VERSION ""

NS_ :

BS_:

BU_: Tester MCU

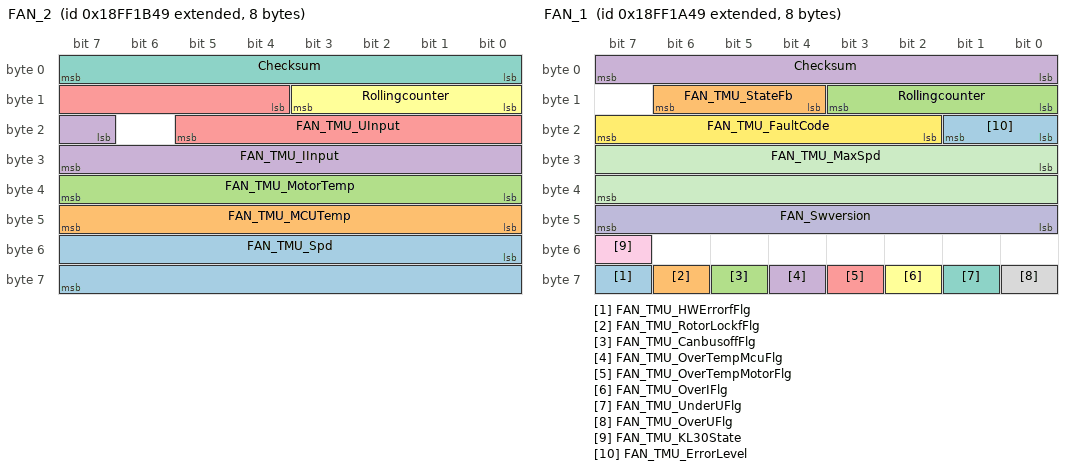
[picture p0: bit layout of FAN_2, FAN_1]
BO_ 2566855497 FAN_2: 8 MCU
 SG_ FAN_TMU_Spd : 48|16@1+ (1,0) [0|6500] ""  Tester
 SG_ FAN_TMU_MCUTemp : 40|8@1+ (1,-40) [-40|210] ""  Tester
 SG_ FAN_TMU_MotorTemp : 32|8@1+ (1,-40) [-40|210] ""  Tester
 SG_ FAN_TMU_IInput : 23|9@1+ (0.1,0) [0|51] ""  Tester
 SG_ FAN_TMU_UInput : 12|10@1+ (1,0) [0|1023] ""  Tester
 SG_ Rollingcounter : 8|4@1+ (1,0) [0|15] ""  Tester
 SG_ Checksum : 0|8@1+ (1,0) [0|255] ""  Tester

BO_ 2566855241 FAN_1: 8 MCU
 SG_ FAN_TMU_HWErrorfFlg : 63|1@1+ (1,0) [0|1] ""  Tester
 SG_ FAN_TMU_RotorLockfFlg : 62|1@1+ (1,0) [0|1] ""  Tester
 SG_ FAN_TMU_CanbusoffFlg : 61|1@1+ (1,0) [0|1] ""  Tester
 SG_ FAN_TMU_OverTempMcuFlg : 60|1@1+ (1,0) [0|1] ""  Tester
 SG_ FAN_TMU_OverTempMotorFlg : 59|1@1+ (1,0) [0|1] ""  Tester
 SG_ FAN_TMU_OverIFlg : 58|1@1+ (1,0) [0|1] ""  Tester
 SG_ FAN_TMU_UnderUFlg : 57|1@1+ (1,0) [0|1] ""  Tester
 SG_ FAN_TMU_OverUFlg : 56|1@1+ (1,0) [0|1] ""  Tester
 SG_ FAN_TMU_KL30State : 55|1@1+ (1,0) [0|1] ""  Tester
 SG_ FAN_Swversion : 40|8@1+ (1,0) [0|255] ""  Tester
 SG_ FAN_TMU_MaxSpd : 24|16@1+ (1,0) [0|6500] ""  Tester
 SG_ FAN_TMU_FaultCode : 18|6@1+ (1,0) [0|63] ""  Tester
 SG_ FAN_TMU_ErrorLevel : 16|2@1+ (1,0) [0|3] ""  Tester
 SG_ FAN_TMU_StateFb : 12|3@1+ (1,0) [0|7] ""  Tester
 SG_ Rollingcounter : 8|4@1+ (1,0) [0|15] ""  Tester
 SG_ Checksum : 0|8@1+ (1,0) [0|255] ""  Tester

BO_ 2566864921 A6_TMU_11: 8 Tester
 SG_ TMU_FAN_SpdReq : 45|16@1+ (1,0) [0|6500] ""  MCU
 SG_ TMU_FAN_ModeReq : 42|3@1+ (1,0) [0|7] ""  MCU

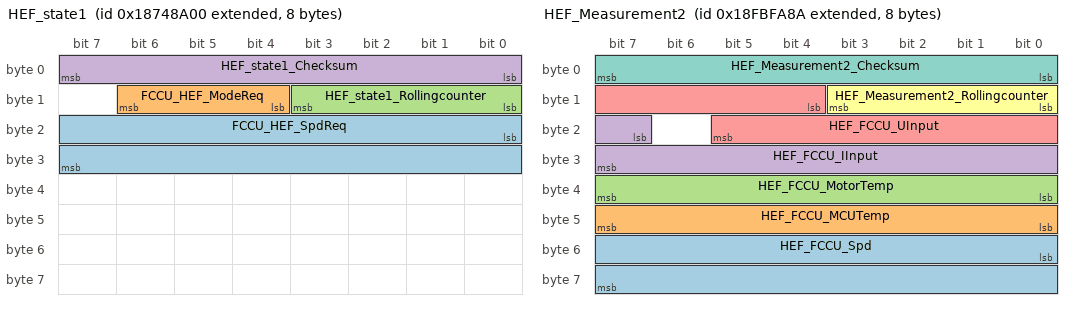
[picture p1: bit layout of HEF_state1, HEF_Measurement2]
BO_ 2557774336 HEF_state1: 8 Tester
 SG_ FCCU_HEF_SpdReq : 16|16@1+ (1,0) [0|6500] "rpm"  MCU
 SG_ FCCU_HEF_ModeReq : 12|3@1+ (1,0) [0|7] ""  MCU
 SG_ HEF_state1_Rollingcounter : 8|4@1+ (1,0) [0|15] ""  MCU
 SG_ HEF_state1_Checksum : 0|8@1+ (1,0) [0|255] ""  MCU

BO_ 2566650506 HEF_Measurement2: 8 MCU
 SG_ HEF_FCCU_Spd : 48|16@1+ (1,0) [0|6500] "rpm"  Tester
 SG_ HEF_FCCU_MCUTemp : 40|8@1+ (1,-40) [-40|210] ""  Tester
 SG_ HEF_FCCU_MotorTemp : 32|8@1+ (1,-40) [-40|210] ""  Tester
 SG_ HEF_FCCU_IInput : 23|9@1+ (0.1,0) [0|51] "A"  Tester
 SG_ HEF_FCCU_UInput : 12|10@1+ (1,0) [0|1023] "V"  Tester
 SG_ HEF_Measurement2_Rollingcounter : 8|4@1+ (1,0) [0|15] ""  Tester
 SG_ HEF_Measurement2_Checksum : 0|8@1+ (1,0) [0|255] ""  Tester

BO_ 2566649994 HEF_Measurement1: 8 MCU
 SG_ HEF_FCCU_HWErrorfFlg : 63|1@1+ (1,0) [0|1] ""  Tester
 SG_ HEF_FCCU_RotorLockfFlg : 62|1@1+ (1,0) [0|1] ""  Tester
 SG_ HEF_FCCU_CanbusoffFlg : 61|1@1+ (1,0) [0|1] ""  Tester
 SG_ HEF_FCCU_OverTempMcuFlg : 60|1@1+ (1,0) [0|1] ""  Tester
 SG_ HEF_FCCU_OverTempMotorFlg : 59|1@1+ (1,0) [0|1] ""  Tester
 SG_ HEF_FCCU_OverIFlg : 58|1@1+ (1,0) [0|1] ""  Tester
 SG_ HEF_FCCU_UnderUFlg : 57|1@1+ (1,0) [0|1] ""  Tester
 SG_ HEF_FCCU_OverUFlg : 56|1@1+ (1,0) [0|1] ""  Tester
 SG_ HEF_FCCU_KL30State : 55|1@1+ (1,0) [0|1] ""  Tester
 SG_ HEF_FCCU_HighVoltageInterlock : 48|2@1+ (1,0) [0|0] "" Vector__XXX
 SG_ HEF_Swversion : 40|8@1+ (1,0) [0|255] ""  Tester
 SG_ HEF_FCCU_MaxSpd : 24|16@1+ (1,0) [0|6500] "rpm"  Tester
 SG_ HEF_FCCU_FaultCode : 18|6@1+ (1,0) [0|63] ""  Tester
 SG_ HEF_FCCU_ErrorLevel : 16|2@1+ (1,0) [0|3] ""  Tester
 SG_ HEF_FCCU_StateFb : 12|3@1+ (1,0) [0|7] ""  Tester
 SG_ HEF_Measurement1_Rollingcounter : 8|4@1+ (1,0) [0|15] ""  Tester
 SG_ HEF_Measurement1_Checksum : 0|8@1+ (1,0) [0|255] ""  Tester

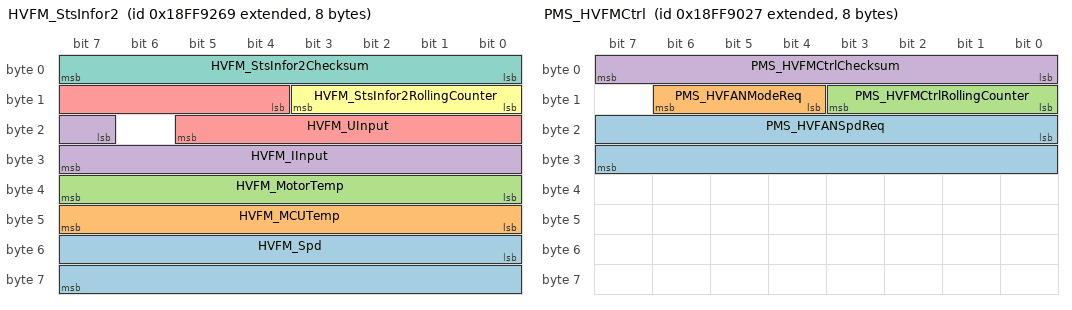
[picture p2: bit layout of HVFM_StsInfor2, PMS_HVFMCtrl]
BO_ 2566885993 HVFM_StsInfor2: 8 MCU
 SG_ HVFM_Spd : 48|16@1+ (1,0) [0|6500] "rpm"  Tester
 SG_ HVFM_MCUTemp : 40|8@1+ (1,-40) [-40|210] ""  Tester
 SG_ HVFM_MotorTemp : 32|8@1+ (1,-40) [-40|210] ""  Tester
 SG_ HVFM_IInput : 23|9@1+ (0.1,0) [0|51] "A"  Tester
 SG_ HVFM_UInput : 12|10@1+ (1,0) [0|1023] "V"  Tester
 SG_ HVFM_StsInfor2RollingCounter : 8|4@1+ (1,0) [0|15] ""  Tester
 SG_ HVFM_StsInfor2Checksum : 0|8@1+ (1,0) [0|255] ""  Tester

BO_ 2566885737 HVFM_StsInfor1: 8 MCU
 SG_ HVFM_HWErrorfFlg : 63|1@1+ (1,0) [0|1] ""  Tester
 SG_ HVFM_RotorLockfFlg : 62|1@1+ (1,0) [0|1] ""  Tester
 SG_ HVFM_CanbusoffFlg : 61|1@1+ (1,0) [0|1] ""  Tester
 SG_ HVFM_OverTempMcuFlg : 60|1@1+ (1,0) [0|1] ""  Tester
 SG_ HVFM_OverTempMotorFlg : 59|1@1+ (1,0) [0|1] ""  Tester
 SG_ HVFM_OverIFlg : 58|1@1+ (1,0) [0|1] ""  Tester
 SG_ HVFM_UnderUFlg : 57|1@1+ (1,0) [0|1] ""  Tester
 SG_ HVFM_OverUFlg : 56|1@1+ (1,0) [0|1] ""  Tester
 SG_ HVFM_KL30State : 55|1@1+ (1,0) [0|1] ""  Tester
 SG_ HVFM_HighVoltageInterlock : 48|2@1+ (1,0) [0|3] ""  Tester
 SG_ HVFM_Swversion : 40|8@1+ (1,0) [0|255] ""  Tester
 SG_ HVFM_MaxSpd : 24|16@1+ (1,0) [0|6500] "rpm"  Tester
 SG_ HVFM_FaultCode : 18|6@1+ (1,0) [0|63] ""  Tester
 SG_ HVFM_ErrorLevel : 16|2@1+ (1,0) [0|3] ""  Tester
 SG_ HVFM_StateFb : 12|3@1+ (1,0) [0|7] ""  Tester
 SG_ HVFM_StsInfor1RollingCounter : 8|4@1+ (1,0) [0|15] ""  Tester
 SG_ HVFM_StsInfor1Checksum : 0|8@1+ (1,0) [0|255] ""  Tester

BO_ 2566885415 PMS_HVFMCtrl: 8 Tester
 SG_ PMS_HVFANSpdReq : 16|16@1+ (1,0) [0|6500] "rpm"  MCU
 SG_ PMS_HVFANModeReq : 12|3@1+ (1,0) [0|7] ""  MCU
 SG_ PMS_HVFMCtrlRollingCounter : 8|4@1+ (1,0) [0|15] ""  MCU
 SG_ PMS_HVFMCtrlChecksum : 0|8@1+ (1,0) [0|255] ""  MCU

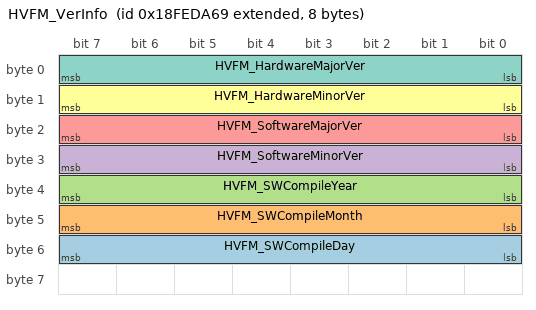
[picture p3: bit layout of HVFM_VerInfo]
BO_ 2566838889 HVFM_VerInfo: 8 MCU
 SG_ HVFM_SWCompileDay : 48|8@1+ (1,0) [0|31] ""  Tester
 SG_ HVFM_SWCompileMonth : 40|8@1+ (1,0) [0|12] ""  Tester
 SG_ HVFM_SWCompileYear : 32|8@1+ (1,2000) [2000|2255] ""  Tester
 SG_ HVFM_SoftwareMinorVer : 24|8@1+ (1,0) [0|255] ""  Tester
 SG_ HVFM_SoftwareMajorVer : 16|8@1+ (1,0) [0|255] ""  Tester
 SG_ HVFM_HardwareMinorVer : 8|8@1+ (1,0) [0|255] ""  Tester
 SG_ HVFM_HardwareMajorVer : 0|8@1+ (1,0) [0|255] ""  Tester

BA_DEF_ SG_  "GenSigSendType" ENUM  "Cyclic","OnWrite","OnWriteWithRepetition","OnChange","OnChangeWithRepetition","IfActive","IfActiveWithRepetition","NoSigSendType";
BA_DEF_ BO_  "VFrameFormat" ENUM  "StandardCAN","ExtendedCAN","reserved","J1939PG","reserved","reserved","reserved","reserved","reserved","reserved","reserved","reserved","reserved","reserved","StandardCAN_FD","ExtendedCAN_FD";
BA_DEF_ BO_  "GenMsgILSupport" ENUM  "No","Yes";
BA_DEF_ BO_  "GenMsgCycleTime" INT 0 300000;
BA_DEF_ BO_  "DiagConnection" INT 0 65535;
BA_DEF_ BO_  "CANFD_BRS" ENUM  "0","1";
BA_DEF_ BU_  "NmAsrNode" ENUM  "No","Yes";
BA_DEF_ BU_  "NmAsrCanMsgReducedTime" INT 0 65535;
BA_DEF_ BU_  "ILUsed" ENUM  "No","Yes";
BA_DEF_  "NmAsrWaitBusSleepTime" INT 0 65535;
BA_DEF_  "NmAsrTimeoutTime" INT 0 65535;
BA_DEF_  "NmAsrRepeatMessageTime" INT 0 65535;
BA_DEF_  "NmAsrMessageCount" INT 0 255;
BA_DEF_  "NmAsrCanMsgCycleTime" INT 0 65535;
BA_DEF_  "NmAsrBaseAddress" HEX 0 65535;
BA_DEF_  "Manufacturer" STRING ;
BA_DEF_  "DBName" STRING ;
BA_DEF_  "Baudrate" INT 1000 1000000;
BA_DEF_  "BaudRateCANFD" INT 1000 10000000;
BA_DEF_DEF_  "GenSigSendType" "Cyclic";
BA_DEF_DEF_  "VFrameFormat" "J1939PG";
BA_DEF_DEF_  "GenMsgILSupport" "Yes";
BA_DEF_DEF_  "GenMsgCycleTime" 0;
BA_DEF_DEF_  "DiagConnection" 57346;
BA_DEF_DEF_  "CANFD_BRS" "1";
BA_DEF_DEF_  "NmAsrNode" "Yes";
BA_DEF_DEF_  "NmAsrCanMsgReducedTime" 50;
BA_DEF_DEF_  "ILUsed" "Yes";
BA_DEF_DEF_  "NmAsrWaitBusSleepTime" 5000;
BA_DEF_DEF_  "NmAsrTimeoutTime" 2000;
BA_DEF_DEF_  "NmAsrRepeatMessageTime" 1500;
BA_DEF_DEF_  "NmAsrMessageCount" 255;
BA_DEF_DEF_  "NmAsrCanMsgCycleTime" 500;
BA_DEF_DEF_  "NmAsrBaseAddress" 1024;
BA_DEF_DEF_  "Manufacturer" "Vector";
BA_DEF_DEF_  "DBName" "";
BA_DEF_DEF_  "Baudrate" 500000;
BA_DEF_DEF_  "BaudRateCANFD" 2000000;
BA_ "DBName" "HVFAN_CANMatrix_Test";
BA_ "VFrameFormat" BO_ 2566855497 1;
BA_ "GenMsgCycleTime" BO_ 2566855497 100;
BA_ "VFrameFormat" BO_ 2566855241 1;
BA_ "GenMsgCycleTime" BO_ 2566855241 500;
BA_ "VFrameFormat" BO_ 2566864921 1;
BA_ "GenMsgCycleTime" BO_ 2566864921 500;
BA_ "VFrameFormat" BO_ 2557774336 1;
BA_ "GenMsgCycleTime" BO_ 2557774336 100;
BA_ "GenMsgCycleTime" BO_ 2566650506 100;
BA_ "VFrameFormat" BO_ 2566650506 1;
BA_ "GenMsgCycleTime" BO_ 2566649994 100;
BA_ "VFrameFormat" BO_ 2566649994 1;
BA_ "GenMsgCycleTime" BO_ 2566885993 100;
BA_ "VFrameFormat" BO_ 2566885993 1;
BA_ "GenMsgCycleTime" BO_ 2566885737 100;
BA_ "VFrameFormat" BO_ 2566885737 1;
BA_ "GenMsgCycleTime" BO_ 2566885415 100;
BA_ "VFrameFormat" BO_ 2566885415 1;
BA_ "GenMsgCycleTime" BO_ 2566838889 1000;
BA_ "VFrameFormat" BO_ 2566838889 1;
